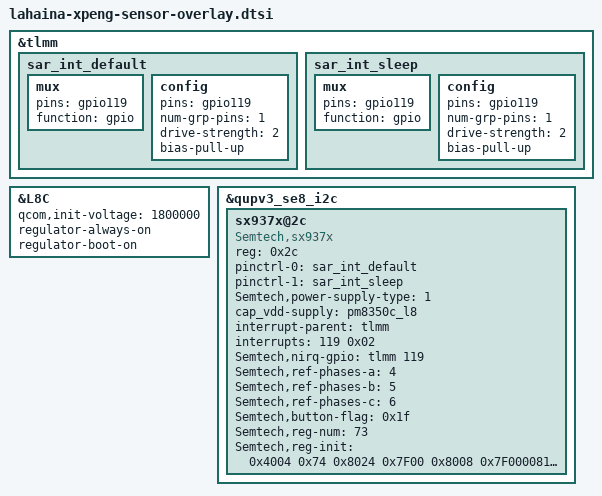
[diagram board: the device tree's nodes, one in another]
/* Copyright (c) 2019, The Linux Foundation. All rights reserved.
 *
 * This program is free software; you can redistribute it and/or modify
 * it under the terms of the GNU General Public License version 2 and
 * only version 2 as published by the Free Software Foundation.
 *
 * This program is distributed in the hope that it will be useful,
 * but WITHOUT ANY WARRANTY; without even the implied warranty of
 * MERCHANTABILITY or FITNESS FOR A PARTICULAR PURPOSE.  See the
 * GNU General Public License for more details.
 */

&tlmm {
	sar_int_default: sar_int_default {
			mux {
				pins = "gpio119";
				function =  "gpio";
			};
			config {
				pins = "gpio119";
				num-grp-pins = <1>;
				drive-strength = <2>;
				bias-pull-up;
			};
	};

	sar_int_sleep: sar_int_sleep {
			mux {
				pins = "gpio119";
				function =  "gpio";
			};
			config {
				pins = "gpio119";
				num-grp-pins = <1>;
				drive-strength = <2>;
				bias-pull-up;
			};
	};
};

&L8C {
	qcom,init-voltage = <1800000>;
	regulator-always-on;
	regulator-boot-on;
	status = "ok";
};

&qupv3_se8_i2c {
	status = "ok";
	sx937x@2c { /* SAR sensor */
		compatible = "Semtech,sx937x";
		reg = <0x2c>;
		pinctrl-names = "default","sleep";
		pinctrl-0 = <&sar_int_default>;
		pinctrl-1 = <&sar_int_sleep>;
		Semtech,power-supply-type = <1>;
		cap_vdd-supply = <&pm8350c_l8>;
		interrupt-parent = <&tlmm>;
		interrupts = <119 0x02>;
		interrupt-names = "sx937x_irq";
		Semtech,nirq-gpio= <&tlmm 119 0x02>;
		/*use PH4/5/6 as the reference sensor
		set it to 0xff if the ref-phases-x is not used*/
		Semtech,ref-phases-a = <4>;
		Semtech,ref-phases-b = <5>;
		Semtech,ref-phases-c = <6>;
		Semtech,button-flag = <0x1f>;
		Semtech,reg-num = <73>;
		Semtech,reg-init = <
			0x4004 0x74
			0x8024 0x7F00
			0x8008 0x7F000081
			0x8020 0x32
			0x8028 0x886
			0x8034 0x886
			0x8040 0x886
			0x804C 0x886
			0x8058 0x886
			0x8064 0x886
			0x8070 0x886
			0x807C 0x886
			0x8030 0xFFF9FD
			0x803C 0xFFD9FF
			0x8048 0xFEF9FF
			0x8054 0xFFF97F
			0x8060 0xBFF9FF
			0x806C 0xFFF9EF
			0x8078 0xF7F9FF
			0x8084 0xBFF9FF
			0x802C 0x954255
			0x8038 0xF543D5
			0x8044 0x9C0270
			0x8050 0x988262
			0x805C 0x9A4269
			0x8068 0xD3C34F
			0x8074 0xB542D5
			0x8080 0x0
			0x8098 0xA141
			0x80B8 0xA040
			0x80D8 0x4D4D
			0x80F8 0x6B6B
			0x8118 0x3333
			0x8138 0x8E
			0x8158 0x8E
			0x8178 0x5A40
			0x80A0 0x202000E1
			0x80C0 0x141400E2
			0x80E0 0xE2
			0x8100 0xD0D00E2
			0x8120 0x171700E2
			0x8140 0x0
			0x8160 0x0
			0x8180 0x0
			0x8188 0x8000015
			0x818C 0x8000016
			0x8190 0x0
			0x8194 0x0
			0x8090 0x3CDE5000
			0x80B0 0x3CD85000
			0x80D0 0x3CD75000
			0x80F0 0x3CDB5000
			0x8110 0x3CCB5000
			0x8130 0x3CD85000
			0x8150 0x3CD85000
			0x8170 0x3CD85000
			0x8088 0x300005
			0x80A8 0x300005
			0x80C8 0x300005
			0x80E8 0x300005
			0x8108 0x300005
			0x8128 0x300000
			0x8148 0x300000
			0x8168 0x300000
			0x808C 0x60200030
			0x80AC 0x60200030
			0x80CC 0x60200030
			0x80EC 0x60200030
			0x810C 0x60200030
			0x812C 0x60200030
			0x814C 0x60200030
			0x816C 0x60200030
			0x8024 0x7F7F
		>;

		status = "ok";
	};
};
